# PIC32MZ1025DAB169 device description
Architecture: MIPS; Family: PIC32MZDA; Series: PIC32MZ
Registers are 32-bit, read-write, no defined reset value unless marked. A register's access mark holds for its fields unless they carry their own. Offsets are from the block's base; [hi:lo] are bit positions; lines under a group give offsets from that group; {n}, {i} and the like mark numbered series; 'fields as' and 'values as' point back to an identical list.

## SB
Instances: SB 0x1f8f8020 in periph_ssx0
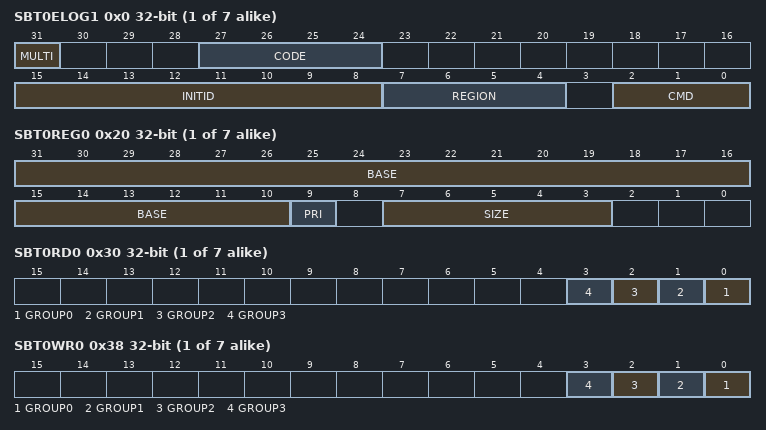
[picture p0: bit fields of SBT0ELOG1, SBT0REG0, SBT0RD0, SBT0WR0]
{0x0+0x400*i} SBT{i}ELOG1 ro (i=0..6) — System Bus Target 'x' Error Log Register 1
  [31] MULTI — Multiple Permission Violations Status bit
    1=Multiple errors have been detected; 0=No multiple errors have been detected
  [27:24] CODE — Error Code bits
    3=Permission violation; 0=No error
  [15:8] INITID — Initiator ID of Requester bits
    14=Crypto Engine; 13=Flash Controller; 12=SQI1; 11=CAN2; 10=CAN1; 9=Ethernet Write; 8=Ethernet Read; 7=USB; 6=DMA Write (DMAPRI (CFGCON) = 1); 5=DMA Write (DMAPRI (CFGCON) = 0); 4=DMA Read (DMAPRI (CFGCON) = 1); 3=DMA Read (DMAPRI (CFGCON) = 0); 2=CPU (CPUPRI (CFGCON) = 1); 1=CPU (CPUPRI (CFGCON) = 0)
  [7:4] REGION — Requested Region Number bits
    1111 - 0000=Targets region that reported a permission group violation
  [2:0] CMD — Transaction Command of the Requester bits
    5=Write (a non-posted write); 3=Read (a locked read caused by a Read-Modify-Write transaction); 2=Read; 1=Write; 0=Idle
{0x4+0x400*i} SBT{i}ELOG2 ro (i=0..6) — System Bus Target 'x' Error Log Register 2
  [1:0] GROUP — Requested Permissions Group bits
    {v}=Group {v} (v=0..3)
{0x8+0x400*i} SBT{i}ECON (i=0..6) — System Bus Target 'x' Error Control Register
  [24] ERRP — Error Control bit
    1=Report protection group violation errors; 0=Do not report protection group violation errors
{0x10+0x400*i} SBT{i}ECLRS ro (i=0..6) — System Bus Target 'x' Single Error Clear Register
  [0] CLEAR
{0x18+0x400*i} SBT{i}ECLRM ro (i=0..6) — System Bus Target 'x' Multiple Error Clear Register
  [0] CLEAR
{0x20+0x400*i} SBT{i}REG0 (i=0..6)
  [31:10] BASE
  [9] PRI — Region Priority Level bit
    1=Level 2; 0=Level 1
  [7:3] SIZE — Region Size bits
    0=Region is not present; 1=Region is 1024 bytes; 2=Region is 2048 bytes; 3=Region is 4096 bytes
{0x30+0x400*i} SBT{i}RD0 (i=0..6)
  [n] GROUP{n} (n=0..3) — Group{n} Read Permissions bits
    1=Privilege Group {n} has read permission; 0=Privilege Group {n} does not have read permission
{0x38+0x400*i} SBT{i}WR0 (i=0..6)
  [n] GROUP{n} (n=0..3) — Group {n} Write Permissions bits
    1=Privilege Group {n} has write permission; 0=Privilege Group {n} does not have write permission
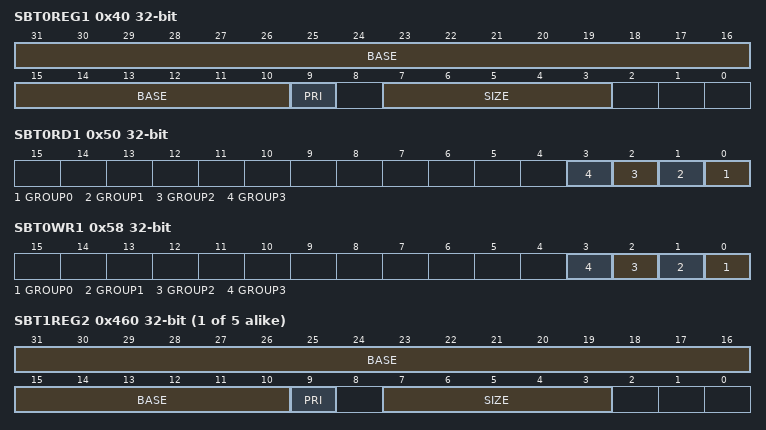
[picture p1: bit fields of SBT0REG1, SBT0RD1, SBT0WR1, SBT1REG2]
0x40 SBT0REG1
  fields as SBT0REG0
0x50 SBT0RD1
  fields as SBT0RD0
0x58 SBT0WR1
  fields as SBT0WR0
{0x60+0x400*i} SBT{i}REG2 (i=1..5)
  fields as SBT0REG0
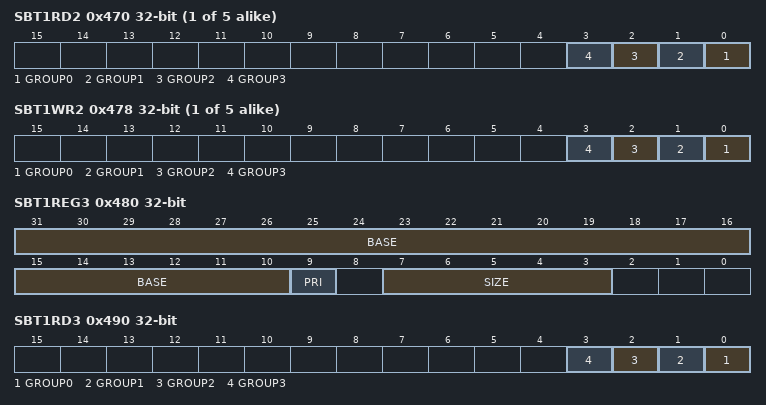
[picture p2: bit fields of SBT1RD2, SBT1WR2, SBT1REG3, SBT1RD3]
{0x70+0x400*i} SBT{i}RD2 (i=1..5)
  fields as SBT0RD0
{0x78+0x400*i} SBT{i}WR2 (i=1..5)
  fields as SBT0WR0
0x480 SBT1REG3
  fields as SBT0REG0
0x490 SBT1RD3
  fields as SBT0RD0
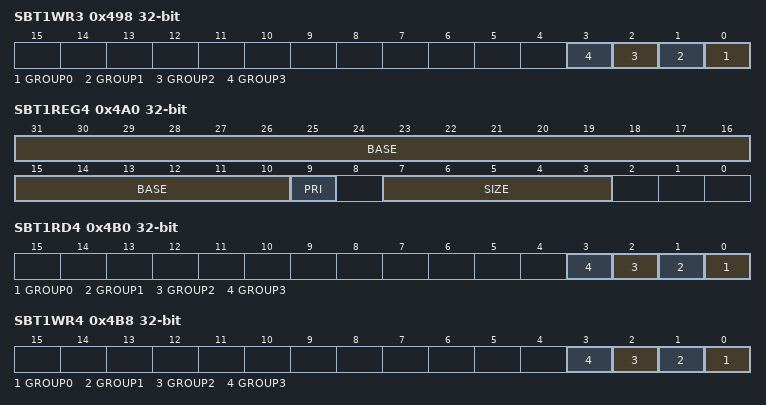
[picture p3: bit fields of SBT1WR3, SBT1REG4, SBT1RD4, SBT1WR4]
0x498 SBT1WR3
  fields as SBT0WR0
0x4A0 SBT1REG4
  fields as SBT0REG0
0x4B0 SBT1RD4
  fields as SBT0RD0
0x4B8 SBT1WR4
  fields as SBT0WR0
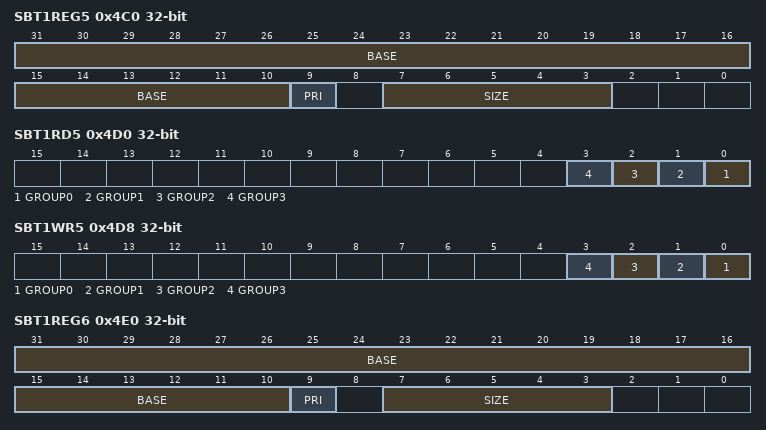
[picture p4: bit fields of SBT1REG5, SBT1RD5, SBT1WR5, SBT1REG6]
0x4C0 SBT1REG5
  fields as SBT0REG0
0x4D0 SBT1RD5
  fields as SBT0RD0
0x4D8 SBT1WR5
  fields as SBT0WR0
0x4E0 SBT1REG6
  fields as SBT0REG0
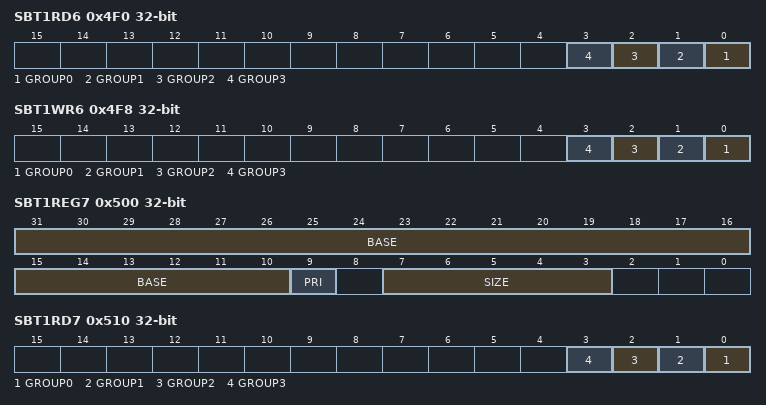
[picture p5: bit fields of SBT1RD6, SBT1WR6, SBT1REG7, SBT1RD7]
0x4F0 SBT1RD6
  fields as SBT0RD0
0x4F8 SBT1WR6
  fields as SBT0WR0
0x500 SBT1REG7
  fields as SBT0REG0
0x510 SBT1RD7
  fields as SBT0RD0
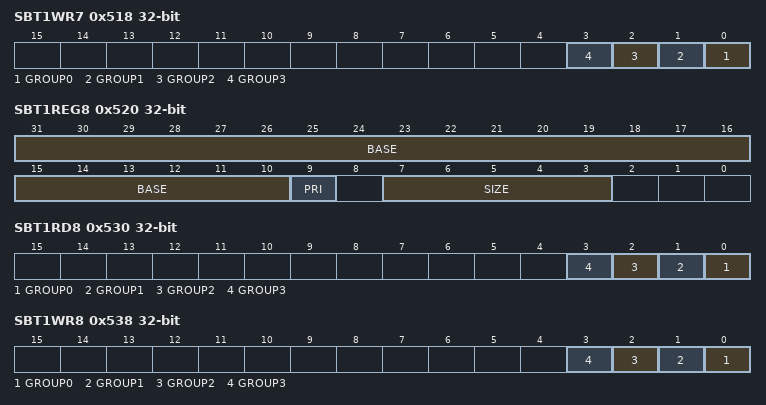
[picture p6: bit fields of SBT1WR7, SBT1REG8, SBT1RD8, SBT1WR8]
0x518 SBT1WR7
  fields as SBT0WR0
0x520 SBT1REG8
  fields as SBT0REG0
0x530 SBT1RD8
  fields as SBT0RD0
0x538 SBT1WR8
  fields as SBT0WR0
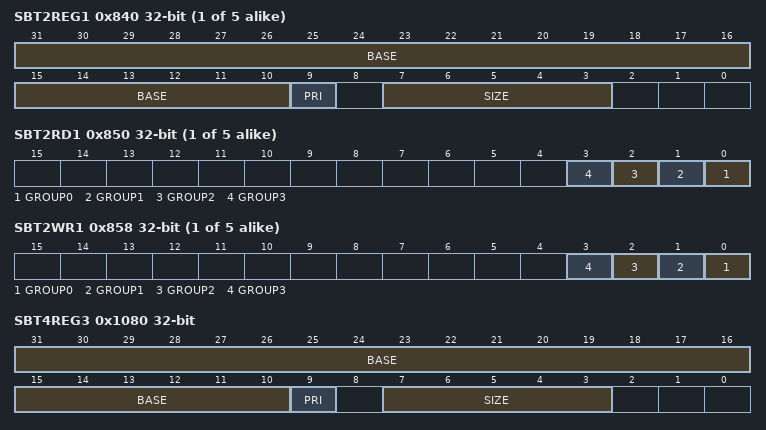
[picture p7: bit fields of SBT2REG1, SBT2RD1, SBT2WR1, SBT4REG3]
{0x40+0x400*i} SBT{i}REG1 (i=2..6)
  fields as SBT0REG0
{0x50+0x400*i} SBT{i}RD1 (i=2..6)
  fields as SBT0RD0
{0x58+0x400*i} SBT{i}WR1 (i=2..6)
  fields as SBT0WR0
0x1080 SBT4REG3
  fields as SBT0REG0
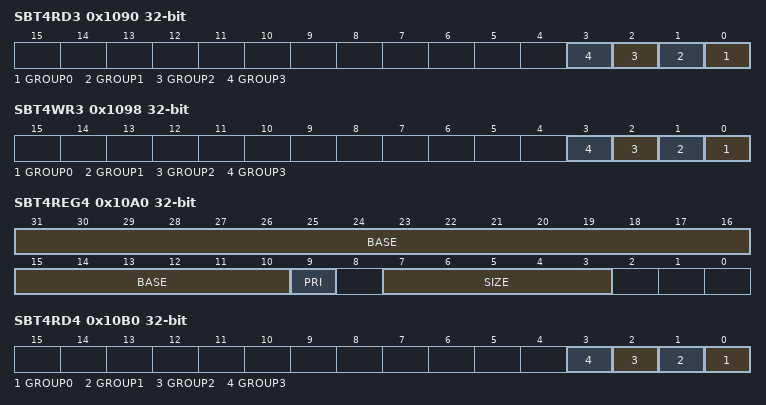
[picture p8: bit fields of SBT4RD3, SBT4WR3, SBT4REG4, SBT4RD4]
0x1090 SBT4RD3
  fields as SBT0RD0
0x1098 SBT4WR3
  fields as SBT0WR0
0x10A0 SBT4REG4
  fields as SBT0REG0
0x10B0 SBT4RD4
  fields as SBT0RD0
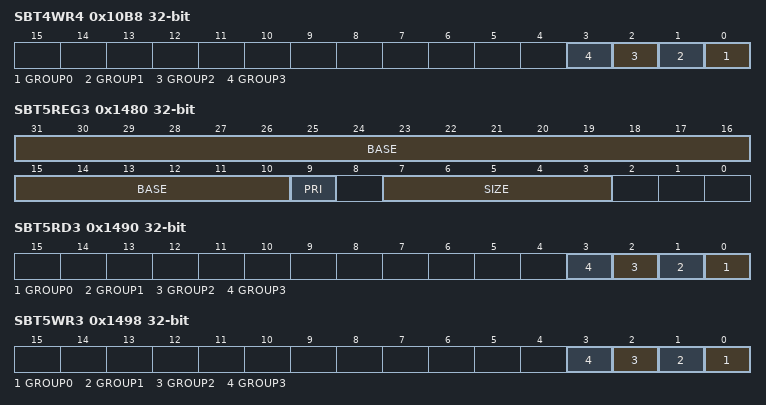
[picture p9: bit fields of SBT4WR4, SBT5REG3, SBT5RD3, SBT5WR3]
0x10B8 SBT4WR4
  fields as SBT0WR0
0x1480 SBT5REG3
  fields as SBT0REG0
0x1490 SBT5RD3
  fields as SBT0RD0
0x1498 SBT5WR3
  fields as SBT0WR0
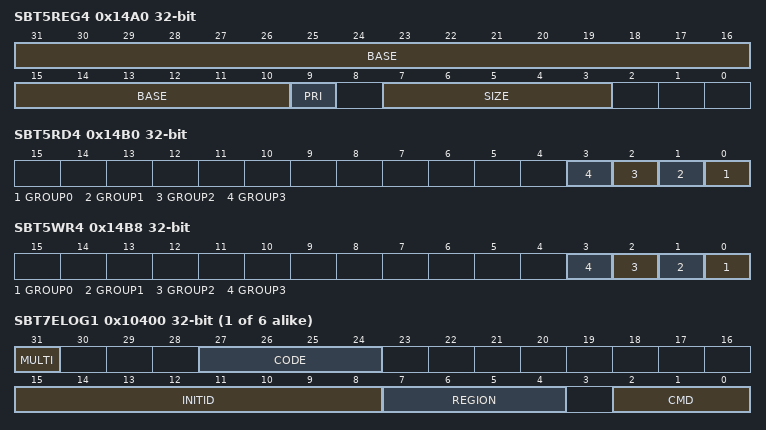
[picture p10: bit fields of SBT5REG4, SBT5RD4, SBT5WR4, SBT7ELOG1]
0x14A0 SBT5REG4
  fields as SBT0REG0
0x14B0 SBT5RD4
  fields as SBT0RD0
0x14B8 SBT5WR4
  fields as SBT0WR0
{0xE800+0x400*i} SBT{i}ELOG1 ro (i=7..12) — System Bus Target 'x' Error Log Register 1
  fields as SBT0ELOG1
{0xE804+0x400*i} SBT{i}ELOG2 ro (i=7..12) — System Bus Target 'x' Error Log Register 2
  fields as SBT0ELOG2
{0xE808+0x400*i} SBT{i}ECON (i=7..12) — System Bus Target 'x' Error Control Register
  fields as SBT0ECON
{0xE810+0x400*i} SBT{i}ECLRS ro (i=7..12) — System Bus Target 'x' Single Error Clear Register
  [0] CLEAR
{0xE818+0x400*i} SBT{i}ECLRM ro (i=7..12) — System Bus Target 'x' Multiple Error Clear Register
  [0] CLEAR
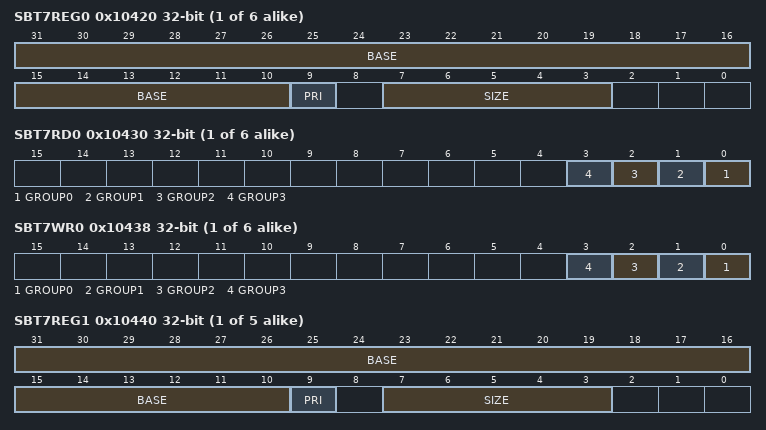
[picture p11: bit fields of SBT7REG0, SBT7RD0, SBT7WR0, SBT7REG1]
{0xE820+0x400*i} SBT{i}REG0 (i=7..12)
  fields as SBT0REG0
{0xE830+0x400*i} SBT{i}RD0 (i=7..12)
  fields as SBT0RD0
{0xE838+0x400*i} SBT{i}WR0 (i=7..12)
  fields as SBT0WR0
{0xE840+0x400*i} SBT{i}REG1 (i=7..11)
  fields as SBT0REG0
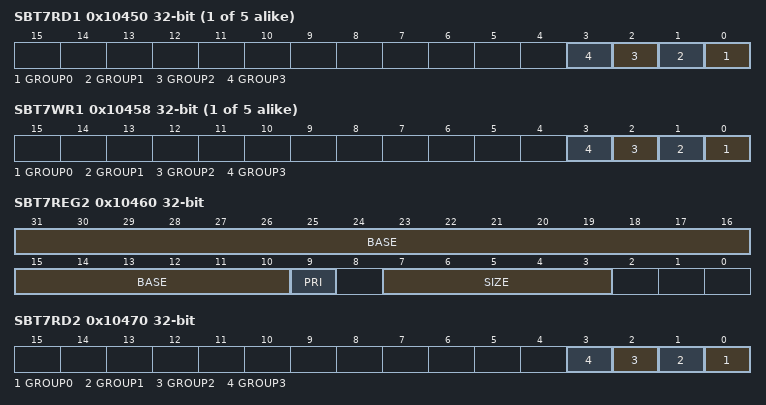
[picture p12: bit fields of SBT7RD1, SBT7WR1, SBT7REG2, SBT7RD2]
{0xE850+0x400*i} SBT{i}RD1 (i=7..11)
  fields as SBT0RD0
{0xE858+0x400*i} SBT{i}WR1 (i=7..11)
  fields as SBT0WR0
0x10460 SBT7REG2
  fields as SBT0REG0
0x10470 SBT7RD2
  fields as SBT0RD0
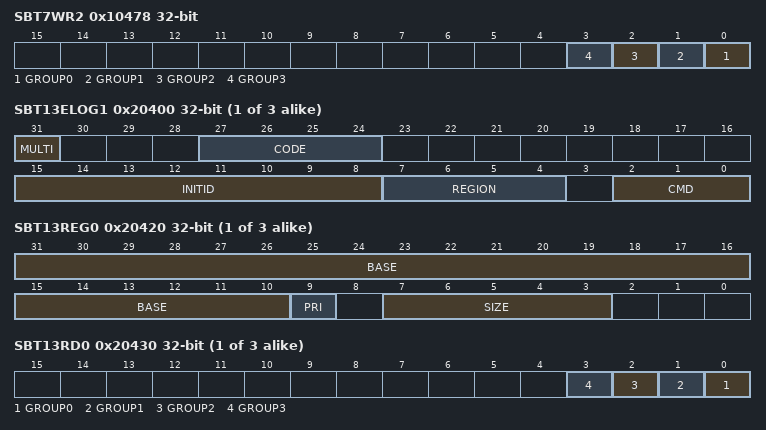
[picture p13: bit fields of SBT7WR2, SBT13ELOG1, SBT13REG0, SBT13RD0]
0x10478 SBT7WR2
  fields as SBT0WR0
{0x1D000+0x400*i} SBT{i}ELOG1 ro (i=13..15) — System Bus Target 'x' Error Log Register 1
  fields as SBT0ELOG1
{0x1D004+0x400*i} SBT{i}ELOG2 ro (i=13..15) — System Bus Target 'x' Error Log Register 2
  fields as SBT0ELOG2
{0x1D008+0x400*i} SBT{i}ECON (i=13..15) — System Bus Target 'x' Error Control Register
  fields as SBT0ECON
{0x1D010+0x400*i} SBT{i}ECLRS ro (i=13..15) — System Bus Target 'x' Single Error Clear Register
  [0] CLEAR
{0x1D018+0x400*i} SBT{i}ECLRM ro (i=13..15) — System Bus Target 'x' Multiple Error Clear Register
  [0] CLEAR
{0x1D020+0x400*i} SBT{i}REG0 (i=13..15)
  fields as SBT0REG0
{0x1D030+0x400*i} SBT{i}RD0 (i=13..15)
  fields as SBT0RD0
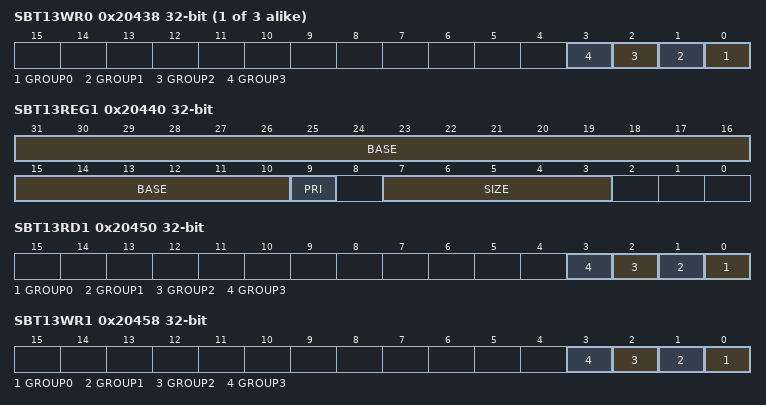
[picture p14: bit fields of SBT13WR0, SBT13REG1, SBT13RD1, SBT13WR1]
{0x1D038+0x400*i} SBT{i}WR0 (i=13..15)
  fields as SBT0WR0
0x20440 SBT13REG1
  fields as SBT0REG0
0x20450 SBT13RD1
  fields as SBT0RD0
0x20458 SBT13WR1
  fields as SBT0WR0
0x20840 SBT14REG1
  fields as SBT0REG0
0x20850 SBT14RD1
  fields as SBT0RD0
0x20858 SBT14WR1
  fields as SBT0WR0
0x34400 SBT16ELOG1 ro — System Bus Target 'x' Error Log Register 1
  fields as SBT0ELOG1
0x34404 SBT16ELOG2 ro — System Bus Target 'x' Error Log Register 2
  fields as SBT0ELOG2
0x34408 SBT16ECON — System Bus Target 'x' Error Control Register
  fields as SBT0ECON
0x34410 SBT16ECLRS ro — System Bus Target 'x' Single Error Clear Register
  [0] CLEAR
0x34418 SBT16ECLRM ro — System Bus Target 'x' Multiple Error Clear Register
  [0] CLEAR
0x34420 SBT16REG0
  fields as SBT0REG0
0x34430 SBT16RD0
  fields as SBT0RD0
0x34438 SBT16WR0
  fields as SBT0WR0
0x34440 SBT16REG1
  fields as SBT0REG0
0x34450 SBT16RD1
  fields as SBT0RD0
0x34458 SBT16WR1
  fields as SBT0WR0
0x34460 SBT16REG2
  fields as SBT0REG0
0x34470 SBT16RD2
  fields as SBT0RD0
0x34478 SBT16WR2
  fields as SBT0WR0
0x34480 SBT16REG3
  fields as SBT0REG0
0x34490 SBT16RD3
  fields as SBT0RD0
0x34498 SBT16WR3
  fields as SBT0WR0
0x344A0 SBT16REG4
  fields as SBT0REG0
0x344B0 SBT16RD4
  fields as SBT0RD0
0x344B8 SBT16WR4
  fields as SBT0WR0

## Notices in the file
Copyright (c) 2017 Microchip Technology Inc.
SPDX-License-Identifier: Apache-2.0
Licensed under the Apache License, Version 2.0 (the "License");
you may not use this file except in compliance with the License.
You may obtain a copy of the License at
http://www.apache.org/licenses/LICENSE-2.0
Unless required by applicable law or agreed to in writing, software
distributed under the License is distributed on an "AS IS" BASIS,
WITHOUT WARRANTIES OR CONDITIONS OF ANY KIND, either express or implied.
See the License for the specific language governing permissions and
limitations under the License.
